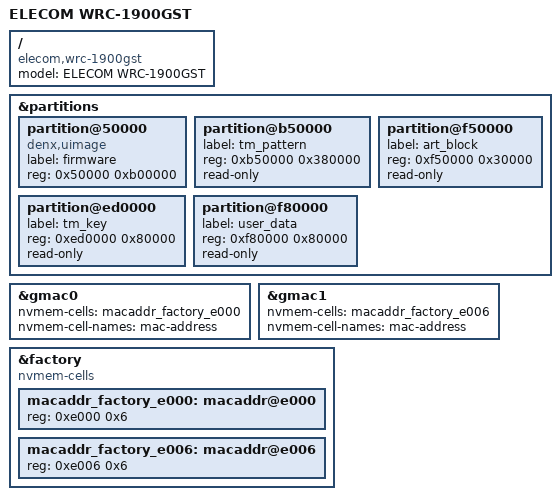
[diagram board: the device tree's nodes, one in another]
// SPDX-License-Identifier: GPL-2.0-only

#include "mt7621_elecom_wrc-gs-2pci.dtsi"

/ {
	compatible = "elecom,wrc-1900gst", "mediatek,mt7621-soc";
	model = "ELECOM WRC-1900GST";
};

&partitions {
	partition@50000 {
		compatible = "denx,uimage";
		label = "firmware";
		reg = <0x50000 0xb00000>;
	};

	partition@b50000 {
		label = "tm_pattern";
		reg = <0xb50000 0x380000>;
		read-only;
	};

	partition@ed0000 {
		label = "tm_key";
		reg = <0xed0000 0x80000>;
		read-only;
	};

	partition@f50000 {
		label = "art_block";
		reg = <0xf50000 0x30000>;
		read-only;
	};

	partition@f80000 {
		label = "user_data";
		reg = <0xf80000 0x80000>;
		read-only;
	};
};

&gmac0 {
	nvmem-cells = <&macaddr_factory_e000>;
	nvmem-cell-names = "mac-address";
};

&gmac1 {
	nvmem-cells = <&macaddr_factory_e006>;
	nvmem-cell-names = "mac-address";
};

&factory {
	compatible = "nvmem-cells";
	#address-cells = <1>;
	#size-cells = <1>;

	macaddr_factory_e000: macaddr@e000 {
		reg = <0xe000 0x6>;
	};

	macaddr_factory_e006: macaddr@e006 {
		reg = <0xe006 0x6>;
	};
};
